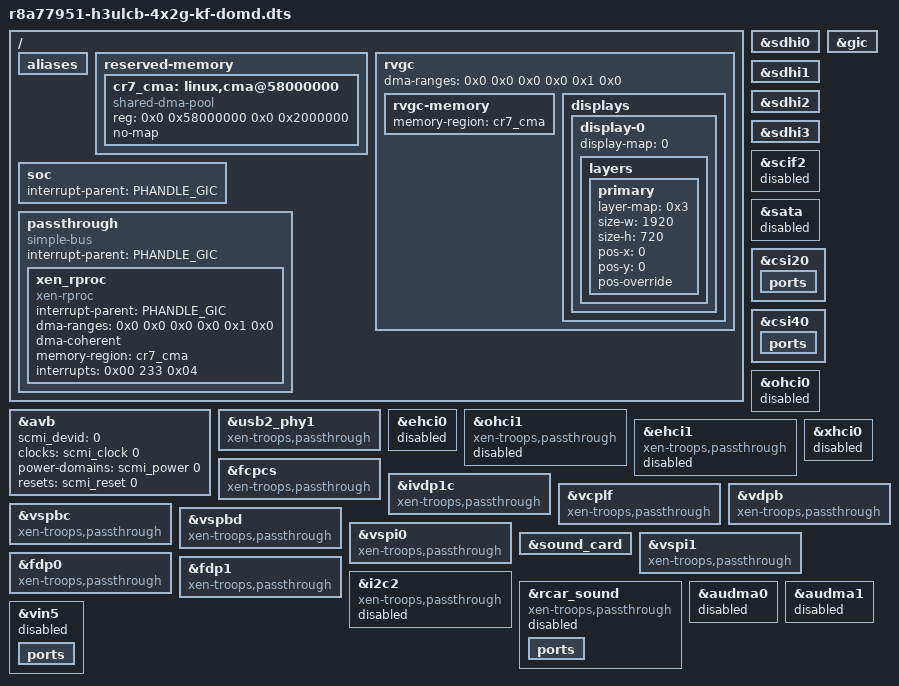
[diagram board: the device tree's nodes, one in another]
// SPDX-License-Identifier: GPL-2.0
/*
 * Device Tree Source for the H3ULCB Kingfisher board
 * running XEN hypervisor
 *
 * Copyright (C) 2016-2018 Renesas Electronics Corp.
 * Copyright (C) 2016 Cogent Embedded, Inc.
 */

#include "r8a77951-ulcb-kf.dts"

/*
 * The device tree compiler (DTC) is allocating the phandle from 1 to
 * onwards. Reserve a high value for the GIC phandle.
 */
#define PHANDLE_GIC (65000)

/ {
	aliases {
		/delete-property/ i2c4;
	};

        reserved-memory {
                #address-cells = <0x2>;
                #size-cells = <0x2>;
                ranges;
                cr7_cma: linux,cma@58000000 {
                        compatible = "shared-dma-pool";
                        reg = <0x0 0x58000000 0x0 0x2000000>;
                        no-map;
                        /delete-property/ reusable;
                        /delete-property/ linux,cma-default;
                };
                /delete-node/ linux,lossy_decompress@54000000;
                /delete-node/ linux,adsp@57000000;
                /delete-node/ linux,multimedia@70000000;
                /delete-node/ linux,cma@57000000;
        };
        /delete-node/ mmngr;
        rvgc {
                dma-ranges = <0x0 0x0 0x0 0x0 0x1 0x0>;
                rvgc-memory {
                        memory-region = <&cr7_cma>;
                };
                displays {
                        display-0 {
                                display-map = <0>;
                                layers {
                                        primary{
                                                /* Layer shold display the information at all display */
                                                layer-map=<0x3>;
                                                size-w=<1920>;
                                                size-h=<720>;
                                                pos-x=<0>;
                                                pos-y=<0>;
                                                pos-override;
                                        };
                                };
                        };
                };
        };

	soc {
		/* This must point to Xen interrupt-parent */
		interrupt-parent = <PHANDLE_GIC>;
	};

	passthrough {
                #address-cells = <0x2>;
                #size-cells = <0x2>;
                interrupt-parent = <PHANDLE_GIC>;
                compatible = "simple-bus";

                xen_rproc {
                        interrupt-parent = <PHANDLE_GIC>;
                        dma-ranges = <0x0 0x0 0x0 0x0 0x1 0x0>;
			dma-coherent;
                        memory-region = <&cr7_cma>;
                        compatible = "xen-rproc";
                        interrupts = <0x00 233 0x04>;
                        interrupt-names = "xen-rproc";
                };
	};

	/*
	 * When creating DT for the guest domain Xen inserts only dummy CPU nodes.
	 * And the number of these inserted CPU nodes is equal to the number of
	 * vCPUs assigned to this domain. All CPU properties which original DT has,
	 * such as OPP, clock, regulator, etc are not passed to the guest’s DT.
	 *
	 * Example of guest vCPU node:
	 *
	 * cpu@0 {
	 *     device_type = "cpu";
	 *     compatible = "arm,armv8";
	 *     enable-method = "psci";
	 *     reg = <0x0>;
	 * };
	 *
	 * This results in the fact that all features expecting a57_x or a53_x
	 * CPU nodes to be present get broken. This is why we have to explicitly
	 * remove the following.
	 */
	/delete-node/thermal-zones;
	/delete-node/pmu_a57;
	/delete-node/pmu_a53;

        /* CR7 is responislbe for graphics */
	/delete-node/ cvbs-in;
	/delete-node/ hdmi-in;
	/delete-node/ hdmi0-out;
	/delete-node/ lvds-decoder;

	/delete-node/ lvds;
	/delete-node/ vga;
	/delete-node/ vga-encoder;
};

/delete-node/&adsp;

&sdhi0 {
	/delete-property/iommus;
};

&sdhi1 {
	/delete-property/iommus;
};

&sdhi2 {
	/delete-property/iommus;
};

&sdhi3 {
	/delete-property/iommus;
};

/* Xen will provide its own GIC, mask ours */
&gic {
	compatible = "";
};

&scif2 {
	status = "disabled";
};

&sata {
	status = "disabled";
};

/* CR7 is responislbe for graphics */
&csi20 {
	/delete-property/ status;
	ports {
		/delete-node/ port@0;
	};
};

&csi40 {
	/delete-property/ status;
	ports {
		/delete-node/ port@0;
	};
};

/delete-node/ &i2c4;
/delete-node/ &fcpvd0;
/delete-node/ &fcpvd1;
/delete-node/ &fcpvd2;
/delete-node/ &vspd0;
/delete-node/ &vspd1;
/delete-node/ &vspd2;
/delete-node/ &du;
/delete-node/ &hdmi0;
/delete-node/ &adv7513_in;
/delete-node/ &hdmi1;
/delete-node/ &lvds0;
/delete-node/ &pciec0;
/delete-node/ &pciec1;
/delete-node/ &mpcie_3v3;
/delete-node/ &mpcie_1v8;
/delete-node/ &vdd_cam_a_0;
/delete-node/ &vdd_cam_a_1;
/delete-node/ &vdd_cam_a_2;
/delete-node/ &vdd_cam_a_3;

&avb {
	scmi_devid = <0>;
	clocks = <&scmi_clock 0>;
	power-domains = <&scmi_power 0>;
	resets = <&scmi_reset 0>;
};

/* These USB controllers are used by DomA/U. */

&usb2_phy1 {
	compatible = "xen-troops,passthrough";
    /delete-property/clocks;
    /delete-property/resets;
    /delete-property/power-domains;
};

&ohci0 {
	status = "disabled";
};

&ehci0 {
	status = "disabled";
};

&ohci1 {
	status = "disabled";
	compatible = "xen-troops,passthrough";
};

&ehci1 {
	status = "disabled";
	compatible = "xen-troops,passthrough";
};

&xhci0 /* usb@ee000000*/
{
	status = "disabled";
};

/* These MM devices are used by DomA/U. */

&fcpcs {
	compatible = "xen-troops,passthrough";
};

&ivdp1c {
	compatible = "xen-troops,passthrough";
        /delete-property/clocks;
        /delete-property/resets;
        /delete-property/power-domains;
};

&vcplf {
	compatible = "xen-troops,passthrough";
        /delete-property/clocks;
        /delete-property/resets;
        /delete-property/power-domains;
};

&vdpb {
	compatible = "xen-troops,passthrough";
        /delete-property/clocks;
        /delete-property/resets;
        /delete-property/power-domains;
};

&vspbc {
	compatible = "xen-troops,passthrough";
};

&vspbd {
	compatible = "xen-troops,passthrough";
};

&vspi0 {
	compatible = "xen-troops,passthrough";
};

&sound_card {
	/delete-property/ dais;
};

&vspi1 {
	compatible = "xen-troops,passthrough";
};

&fdp0 {
	compatible = "xen-troops,passthrough";
};

&fdp1 {
	compatible = "xen-troops,passthrough";
};

&i2c2 {
	status = "disabled";
	compatible = "xen-troops,passthrough";
	/delete-property/power-domains;
	/delete-property/dmas;
	/delete-property/dma-names;
};

&rcar_sound {
	status = "disabled";
	compatible = "xen-troops,passthrough";
	/delete-property/power-domains;
	
	ports {
		/* HDMI snd in is not availble anymore */
		/delete-node/ port@1;
	};
};

&audma0 /* dma-controller@ec700000*/
{
	status = "disabled";
};

&audma1 /* dma-controller@ec720000*/
{
	status = "disabled";
};

&vin5 {
    /delete-property/clocks;
    /delete-property/resets;
    /delete-property/power-domains;
    status = "disabled";
	ports {
		/delete-node/ port@0;
	};
};
